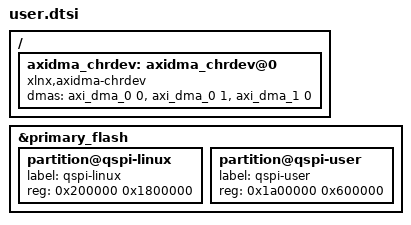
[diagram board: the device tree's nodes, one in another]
/ {
    axidma_chrdev: axidma_chrdev@0 {
        compatible = "xlnx,axidma-chrdev";
        dmas = <&axi_dma_0 0 &axi_dma_0 1 &axi_dma_1 0>;
        dma-names = "tx_channel", "rx_channel", "tx_channel_1";
    };
};

&primary_flash {
		partition@qspi-linux {
			label = "qspi-linux";
			reg = <0x200000 0x1800000>; /* 24M */
		};
        partition@qspi-user {
			label = "qspi-user";
			reg = <0x1a00000 0x600000>; /* 6M */
		};
	};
